# NUC1xx_registers register map
File version: 0.1
CPU: 
Registers are 32-bit, read-write, reset 0x0 unless marked. A register's access mark holds for its fields unless they carry their own. Offsets are from the block's base; [hi:lo] are bit positions; lines under a group give offsets from that group.

## TMR0 — Registers group
Base 0x40010000
Same registers: TMR1 0x40010020, TMR2 0x40110000, TMR3 0x40110020
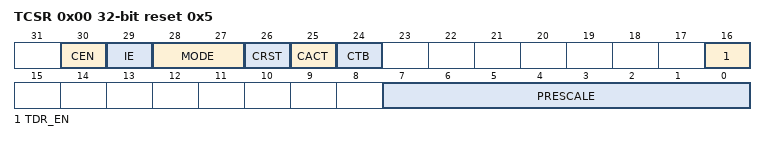
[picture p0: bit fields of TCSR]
0x00 TCSR reset 0x5 (reset mask 0xFFFFFFFA) — Timer0 Control and Status Register
  [30] CEN — Timer Enable Bit 1 = Starts counting 0 = Stops/Suspends counting Note1: In stop status, and then set CEN to 1 will enables the 24-bit up-timer keeps up counting from the last stop counting value. Note2: This bit is auto-cleared by hardware in one-shot mode (MODE[28:27]=00) when the associated timer interrupt is generated (IE[29]=1).
  [29] IE — Interrupt Enable Bit 1 = Enable timer Interrupt. 0 = Disable timer Interrupt. If timer interrupt is enabled, the timer asserts its interrupt signal when the associated up-timer value is equal to TCMPR.
  [28:27] MODE — Timer Operating Mode MODE Timer Operating Mode 00 The timer is operating in the one-shot mode. The associated interrupt signal is generated once (if IE is enabled) and CEN is automatically cleared by hardware. 01 The timer is operating in the periodic mode. The associated interrupt signal is generated periodically (if IE is enabled). 10 The timer is operating in the toggle mode. The interrupt signal is generated periodically (if IE is enabled). And the associated signal (tout) is changing back and forth with 50% duty cycle. (This mode only supported in Low Density) 11 The timer is operating in auto-reload counting mode. The associated interrupt signal is generated when TDR = TCMPR (if IE is enabled); however, the 24-bit up-timer counts continuously without reset. (This mode only supported in Low Density)
  [26] CRST — Timer Reset Bit Set this bit will reset the 24-bit up-timer, 8-bit pre-scale counter and also force CEN to 0. 0 = No effect. 1 = Reset Timer's 8-bit pre-scale counter, internal 24-bit up-timer and CEN bit.
  [25] CACT ro — Timer Active Status Bit (Read only) This bit indicates the up-timer status. 0 = Timer is not active. 1 = Timer is active.
  [24] CTB — Counter Mode Enable Bit (Low Density only) This bit is the counter mode enable bit. When Timer is used as an event counter, this bit should be set to 1 and Timer will work as an event counter triggered by raising edge of external pin. 1 = Enable counter mode 0 = Disable counter mode
  [16] TDR_EN — Data Load Enable When TDR_EN is set, TDR (Timer Data Register) will be updated continuously with the 24-bit up-timer value as the timer is counting. 1 = Timer Data Register update enable. 0 = Timer Data Register update disable.
  [7:0] PRESCALE — Pre-scale Counter Clock input is divided by PRESCALE+1 before it is fed to the counter. If PRESCALE=0, then there is no scaling.
0x04 TCMPR — Timer0 Compare Register
  [23:0] TCMP — Timer Compared Value TCMP is a 24-bit compared register. When the internal 24-bit up-timer counts and its value is equal to TCMP value, a Timer Interrupt is requested if the timer interrupt is enabled with TCSR.IE[29]=1. The TCMP value defines the timer counting cycle time. Time out period = (Period of timer clock input) * (8-bit PRESCALE + 1) * (24-bit TCMP) NOTE1: Never write 0x0 or 0x1 in TCMP, or the core will run into unknown state. NOTE2: No matter CEN is 0 or 1, whenever software write a new value into this register, TIMER will restart counting using this new value and abort previous count.
0x08 TISR — Timer0 Interrupt Status Register
  [0] TIF write-1-clears — Timer Interrupt Flag This bit indicates the interrupt status of Timer. TIF bit is set by hardware when the up counting value of internal 24-bit timer matches the timer compared value (TCMP). It is cleared by writing 1 to this bit.
0x0C TDR ro — Timer0 Data Register
  [23:0] TDR — Timer Data Register When TCSR.TDR_EN is set to 1, the internal 24-bit up-timer value will be loaded into TDR. User can read this register for the up-timer value.
